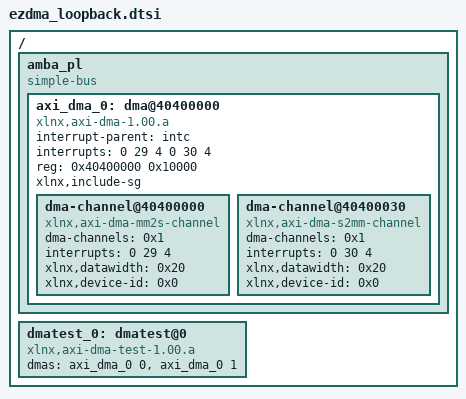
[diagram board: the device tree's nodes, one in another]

/ {
	amba_pl: amba_pl {
		#address-cells = <1>;
		#size-cells = <1>;
		compatible = "simple-bus";
		ranges ;
		axi_dma_0: dma@40400000 {
			#dma-cells = <1>;
			compatible = "xlnx,axi-dma-1.00.a";
			interrupt-parent = <&intc>;
			interrupts = <0 29 4 0 30 4>;
			reg = <0x40400000 0x10000>;
			xlnx,include-sg ;
			dma-channel@40400000 {
				compatible = "xlnx,axi-dma-mm2s-channel";
				dma-channels = <0x1>;
				interrupts = <0 29 4>;
				xlnx,datawidth = <0x20>;
				xlnx,device-id = <0x0>;
			};
			dma-channel@40400030 {
				compatible = "xlnx,axi-dma-s2mm-channel";
				dma-channels = <0x1>;
				interrupts = <0 30 4>;
				xlnx,datawidth = <0x20>;
				xlnx,device-id = <0x0>;
			};
		};
	};
        dmatest_0: dmatest@0 {
                compatible ="xlnx,axi-dma-test-1.00.a";
                dmas = <&axi_dma_0 0
                        &axi_dma_0 1>;
                dma-names = "dma0", "dma1";
        } ;
};

